# PY32F002Bxx register map
Vendor: Puya; Series: PY32F0; File version: 1.0.0
CPU: CM0+ r0p1, little endian, no MPU, no FPU, 4 interrupt priority bits
Registers are 32-bit, read-write, reset 0x0 unless marked. A register's access mark holds for its fields unless they carry their own. Offsets are from the block's base; [hi:lo] are bit positions; {n}, {i} and the like mark numbered series; 'fields as' and 'values as' point back to an identical list.

## TIM1 — Advanced timer
Base 0x40012C00
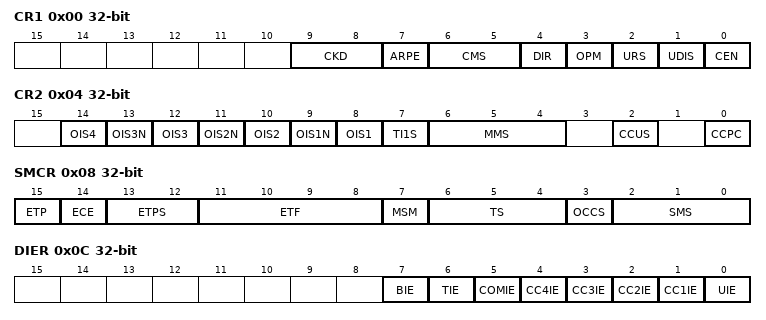
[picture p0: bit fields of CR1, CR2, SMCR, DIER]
0x00 CR1
  [9:8] CKD
    0=Div1 (t_DTS = t_CK_INT); 1=Div2 (t_DTS = 2 x t_CK_INT); 2=Div4 (t_DTS = 4 x t_CK_INT)
  [7] ARPE
    0=Disabled (TIMx_APRR register is not buffered); 1=Enabled (TIMx_APRR register is buffered)
  [6:5] CMS
    0=EdgeAligned (The counter counts up or down depending on the direction bit); 1=CenterAligned1 (The counter counts up and down alternatively. Output compare interrupt flags are set only when the counter is counting down.); 2=CenterAligned2 (The counter counts up and down alternatively. Output compare interrupt flags are set only when the counter is counting up.); 3=CenterAligned3 (The counter counts up and down alternatively. Output compare interrupt flags are set both when the counter is counting up or down.)
  [4] DIR
    0=Up (Counter used as upcounter); 1=Down (Counter used as downcounter)
  [3] OPM
    0=Disabled (Counter is not stopped at update event); 1=Enabled (Counter stops counting at the next update event (clearing the CEN bit))
  [2] URS
    0=AnyEvent (Any of counter overflow/underflow, setting UG, or update through slave mode, generates an update interrupt or DMA request); 1=CounterOnly (Only counter overflow/underflow generates an update interrupt or DMA request)
  [1] UDIS
    0=Enabled (Update event enabled); 1=Disabled (Update event disabled)
  [0] CEN
    0=Disabled (Counter disabled); 1=Enabled (Counter enabled)
0x04 CR2 (reset mask 0xF8)
  [2n+6] OIS{n} (n=1..4)
  [13] OIS3N
  [11] OIS2N
  [9] OIS1N
  [7] TI1S
    0=Normal (The TIMx_CH1 pin is connected to TI1 input); 1=XOR (The TIMx_CH1, CH2, CH3 pins are connected to TI1 input)
  [6:4] MMS
    0=Reset (The UG bit from the TIMx_EGR register is used as trigger output); 1=Enable (The counter enable signal, CNT_EN, is used as trigger output); 2=Update (The update event is selected as trigger output); 3=ComparePulse (The trigger output send a positive pulse when the CC1IF flag it to be set, as soon as a capture or a compare match occurred); {v}=CompareOC{v-3} (OC{v-3}REF signal is used as trigger output) (v=4..7)
  [2] CCUS
    0=Bit (When capture/compare control bits are preloaded (CCPC=1), they are updated by setting the COMG bit only); 1=BitOrEdge (When capture/compare control bits are preloaded (CCPC=1), they are updated by setting the COMG bit or when an rising edge occurs on TRGI)
  [0] CCPC
0x08 SMCR (reset mask 0xFFF7)
  [15] ETP
    0=NotInverted (ETR is noninverted, active at high level or rising edge); 1=Inverted (ETR is inverted, active at low level or falling edge)
  [14] ECE
    0=Disabled (External clock mode 2 disabled); 1=Enabled (External clock mode 2 enabled. The counter is clocked by any active edge on the ETRF signal.)
  [13:12] ETPS
    0=Div1 (Prescaler OFF); 1=Div2 (ETRP frequency divided by 2); 2=Div4 (ETRP frequency divided by 4); 3=Div8 (ETRP frequency divided by 8)
  [11:8] ETF
    0=No filter, sampling is done at fDTS; 1=FCK_INT_N2 (fSAMPLING=fCK_INT, N=2); 2=FCK_INT_N4 (fSAMPLING=fCK_INT, N=4); 3=FCK_INT_N8 (fSAMPLING=fCK_INT, N=8); 4=FDTS_Div2_N6 (fSAMPLING=fDTS/2, N=6); 5=FDTS_Div2_N8 (fSAMPLING=fDTS/2, N=8); 6=FDTS_Div4_N6 (fSAMPLING=fDTS/4, N=6); 7=FDTS_Div4_N8 (fSAMPLING=fDTS/4, N=8); 8=FDTS_Div8_N6 (fSAMPLING=fDTS/8, N=6); 9=FDTS_Div8_N8 (fSAMPLING=fDTS/8, N=8); 10=FDTS_Div16_N5 (fSAMPLING=fDTS/16, N=5); 11=FDTS_Div16_N6 (fSAMPLING=fDTS/16, N=6); 12=FDTS_Div16_N8 (fSAMPLING=fDTS/16, N=8); 13=FDTS_Div32_N5 (fSAMPLING=fDTS/32, N=5); 14=FDTS_Div32_N6 (fSAMPLING=fDTS/32, N=6); 15=FDTS_Div32_N8 (fSAMPLING=fDTS/32, N=8)
  [7] MSM
    0=NoSync (No action); 1=Sync (The effect of an event on the trigger input (TRGI) is delayed to allow a perfect synchronization between the current timer and its slaves (through TRGO). It is useful if we want to synchronize several timers on a single external event.)
  [6:4] TS
    0=ITR0 (Internal Trigger 0 (ITR0)); 1=ITR1 (Internal Trigger 1 (ITR1)); 2=ITR2 (Internal Trigger 2 (ITR2)); 4=TI1F_ED (TI1 Edge Detector (TI1F_ED)); 5=TI1FP1 (Filtered Timer Input 1 (TI1FP1)); 6=TI2FP2 (Filtered Timer Input 2 (TI2FP2)); 7=ETRF (External Trigger input (ETRF))
  [3] OCCS
  [2:0] SMS
    0=Disabled (Slave mode disabled - if CEN = ‘1 then the prescaler is clocked directly by the internal clock.); 1=Encoder mode 1 - Counter counts up/down on TI2FP1 edge depending on TI1FP2 level; 2=Encoder mode 2 - Counter counts up/down on TI1FP2 edge depending on TI2FP1 level; 3=Encoder mode 3 - Counter counts up/down on both TI1FP1 and TI2FP2 edges depending on the level of the other input; 4=Reset Mode - Rising edge of the selected trigger input (TRGI) reinitializes the counter and generates an update of the registers; 5=Gated Mode - The counter clock is enabled when the trigger input (TRGI) is high. The counter stops (but is not reset) as soon as the trigger becomes low. Both start and stop of the counter are controlled.; 6=Trigger Mode - The counter starts at a rising edge of the trigger TRGI (but it is not reset). Only the start of the counter is controlled.; 7=Ext_Clock_Mode (External Clock Mode 1 - Rising edges of the selected trigger (TRGI) clock the counter.)
0x0C DIER (reset mask 0x5F5F)
  [7] BIE
    0=Disabled (Break interrupt disabled); 1=Enabled (Break interrupt enabled)
  [6] TIE
    0=Disabled (Trigger interrupt disabled); 1=Enabled (Trigger interrupt enabled)
  [5] COMIE
    0=Disabled (COM interrupt disabled); 1=Enabled (COM interrupt enabled)
  [n] CC{n}IE (n=1..4)
    0=Disabled (CCx interrupt disabled); 1=Enabled (CCx interrupt enabled)
  [0] UIE
    0=Disabled (Update interrupt disabled); 1=Enabled (Update interrupt enabled)
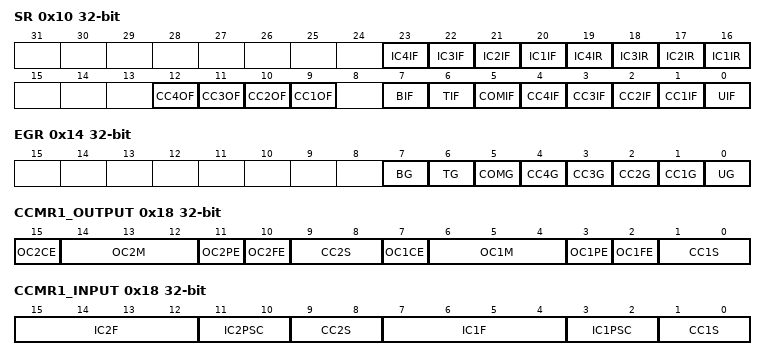
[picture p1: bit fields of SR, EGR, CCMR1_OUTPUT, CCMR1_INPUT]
0x10 SR (reset mask 0x1E5F)
  [23] IC4IF — desc IC3IF
  [22] IC3IF
  [21] IC2IF
  [20] IC1IF
  [19] IC4IR — desc IC3IR
  [18] IC3IR
  [17] IC2IR
  [16] IC1IR
  [n+8] CC{n}OF write-0-clears (n=1..4)
    on read: 1=Overcapture (The counter value has been captured in TIMx_CCRx register while CCxIF flag was already set) | on write: 0=Clear flag
  [7] BIF
  [6] TIF write-0-clears
    on read: 0=No trigger event occurred; 1=Trigger interrupt pending | on write: 0=Clear flag
  [5] COMIF
  [n] CC{n}IF write-0-clears (n=1..4)
    on read: 1=Match (If CC1 is an output: The content of the counter TIMx_CNT matches the content of the TIMx_CCR1 register. If CC1 is an input: The counter value has been captured in TIMx_CCR1 register.) | on write: 0=Clear flag
  [0] UIF
0x14 EGR wo (reset mask 0x5F)
  [7] BG
  [6] TG
    1=Trigger (The TIF flag is set in TIMx_SR register. Related interrupt or DMA transfer can occur if enabled.)
  [5] COMG
  [4] CC4G
  [3] CC3G
  [2] CC2G
  [1] CC1G — Capture/Compare 1 Generation
  [0] UG
    1=Trigger (Re-initializes the timer counter and generates an update of the registers.)
0x18 CCMR1_OUTPUT
  [15] OC2CE
  [14:12] OC2M
    0=Frozen (The comparison between the output compare register TIMx_CCRy and the counter TIMx_CNT has no effect on the outputs / OpmMode1: Retriggerable OPM mode 1 - In up-counting mode, the channel is active until a trigger event is detected (on TRGI signal). In down-counting mode, the channel is inactive); 1=ActiveOnMatch (Set channel to active level on match. OCyREF signal is forced high when the counter matches the capture/compare register / OpmMode2: Inversely to OpmMode1); 2=InactiveOnMatch (Set channel to inactive level on match. OCyREF signal is forced low when the counter matches the capture/compare register / Reserved); 3=Toggle (OCyREF toggles when TIMx_CNT=TIMx_CCRy / Reserved); 4=ForceInactive (OCyREF is forced low / CombinedPwmMode1: OCyREF has the same behavior as in PWM mode 1. OCyREFC is the logical OR between OC1REF and OC2REF); 5=ForceActive (OCyREF is forced high / CombinedPwmMode2: OCyREF has the same behavior as in PWM mode 2. OCyREFC is the logical AND between OC1REF and OC2REF); 6=PwmMode1 (In upcounting, channel is active as long as TIMx_CNT<TIMx_CCRy else inactive. In downcounting, channel is inactive as long as TIMx_CNT>TIMx_CCRy else active / AsymmetricPwmMode1: OCyREF has the same behavior as in PWM mode 1. OCyREFC outputs OC1REF when the counter is counting up, OC2REF when it is counting down); 7=PwmMode2 (Inversely to PwmMode1 / AsymmetricPwmMode2: Inversely to AsymmetricPwmMode1)
  [11] OC2PE
    0=Disabled (Preload register on CCR2 disabled. New values written to CCR2 are taken into account immediately); 1=Enabled (Preload register on CCR2 enabled. Preload value is loaded into active register on each update event)
  [10] OC2FE
  [9:8] CC2S
    0=Output (CC2 channel is configured as output)
  [7] OC1CE
  [6:4] OC1M
    values as OC2M
  [3] OC1PE
  [2] OC1FE
  [1:0] CC1S
0x18 CCMR1_INPUT (alternate view of CCMR1_OUTPUT)
  [15:12] IC2F
  [11:10] IC2PSC
  [9:8] CC2S
    1=TI2 (CC2 channel is configured as input, IC2 is mapped on TI2); 2=TI1 (CC2 channel is configured as input, IC2 is mapped on TI1); 3=TRC (CC2 channel is configured as input, IC2 is mapped on TRC)
  [7:4] IC1F
  [3:2] IC1PSC
  [1:0] CC1S
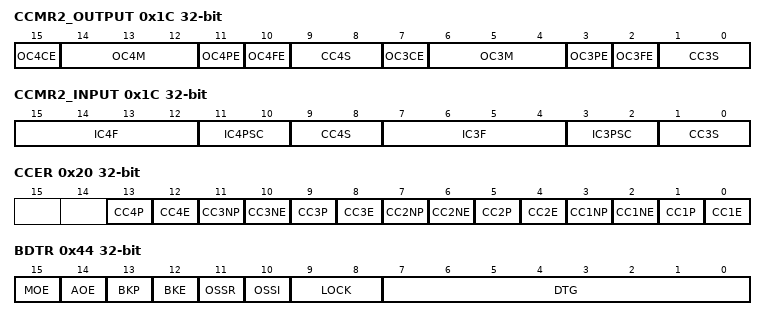
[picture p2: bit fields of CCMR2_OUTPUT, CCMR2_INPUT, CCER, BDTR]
0x1C CCMR2_OUTPUT
  [15] OC4CE
  [14:12] OC4M
    values as CCMR1_OUTPUT.OC2M
  [11] OC4PE
    0=Disabled (Preload register on CCRx disabled. New values written to CCRx are taken into account immediately); 1=Enabled (Preload register on CCRx enabled. Preload value is loaded into active register on each update event)
  [10] OC4FE
  [9:8] CC4S
    0=Output (CCx channel is configured as output)
  [7] OC3CE
  [6:4] OC3M
    values as CCMR1_OUTPUT.OC2M
  [3] OC3PE
    values as OC4PE
  [2] OC3FE
  [1:0] CC3S
    0=Output (CCx channel is configured as output)
0x1C CCMR2_INPUT (alternate view of CCMR2_OUTPUT)
  [15:12] IC4F
  [11:10] IC4PSC
  [9:8] CC4S
    0=Output (CC4 channel is configured as output); 1=TI4 (CC4 channel is configured as input, IC4 is mapped on TI4); 2=TI3 (CC4 channel is configured as input, IC4 is mapped on TI3); 3=TRC (CC4 channel is configured as input, IC4 is mapped on TRC)
  [7:4] IC3F
  [3:2] IC3PSC
  [1:0] CC3S
    0=Output (CC3 channel is configured as output); 1=TI3 (CC3 channel is configured as input, IC3 is mapped on TI3); 2=TI4 (CC3 channel is configured as input, IC3 is mapped on TI4); 3=TRC (CC3 channel is configured as input, IC3 is mapped on TRC)
0x20 CCER (reset mask 0x3333)
  [4n-3] CC{n}P (n=1..4), [4n-4] CC{n}E (n=1..4), [11] CC3NP, [10] CC3NE, [7] CC2NP, [6] CC2NE, [3] CC1NP, [2] CC1NE
0x24 CNT
  [15:0] CNT
0x28 PSC
  [15:0] PSC
0x2C ARR reset 0xFFFF
  [15:0] ARR
0x30 RCR reset 0xFFFF
  [7:0] REP
{0x30+4i} CCR{i} (i=1..4) — desc CCR{i}
  [15:0] CCR — desc CCR1
0x44 BDTR
  [15] MOE, [14] AOE, [13] BKP, [12] BKE, [11] OSSR, [10] OSSI, [9:8] LOCK, [7:0] DTG
